# main_sec_mmr_MAIN_SEC_MMR_CFG2_45900000h register map
Vendor: Texas Instruments
Peripheral module from a debugger description file (folder am62D).
Registers are 32-bit, access per field, reset 0xAA unless marked. A register's access mark holds for its fields unless they carry their own. Offsets are as the file gives them; lines under a group give offsets from that group; [hi:lo] are bit positions; {n}, {i} and the like mark numbered series; 'fields as' and 'values as' point back to an identical list; <NAME> marks a mode.

## main_sec_mmr_CFG2
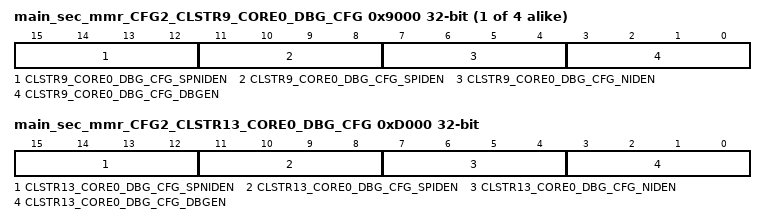
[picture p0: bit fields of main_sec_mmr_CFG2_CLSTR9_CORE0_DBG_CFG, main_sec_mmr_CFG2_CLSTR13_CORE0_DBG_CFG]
{0x9000+0x40*i} main_sec_mmr_CFG2_CLSTR9_CORE{i}_DBG_CFG (i=0..3)
  [15:12] CLSTR9_CORE{i}_DBG_CFG_SPNIDEN ro — Core{i} Secure Non-Invasive debug activate.This is a fault tolerant bitfield that must be set 4'hA to activate4'b1010 - Activatedothers - Deactivated Reset Source: sys_por_rst_n
  [11:8] CLSTR9_CORE{i}_DBG_CFG_SPIDEN ro — Core{i} Secure Invasive debug activate.This is a fault tolerant bitfield that must be set 4'hA to activate4'b1010 - Activatedothers - Deactivated Reset Source: sys_por_rst_n
  [7:4] CLSTR9_CORE{i}_DBG_CFG_NIDEN rw — Core{i} Non-Invasive debug activate.This is a fault tolerant bitfield that must be set 4'hA to activate4'b1010 - Activatedothers - Deactivated Reset Source: sys_por_rst_n
  [3:0] CLSTR9_CORE{i}_DBG_CFG_DBGEN rw — Core{i} Invasive debug activate.This is a fault tolerant bitfield that must be set 4'hA to activate4'b1010 - Activatedothers - Deactivated Reset Source: sys_por_rst_n
0xD000 main_sec_mmr_CFG2_CLSTR13_CORE0_DBG_CFG
  [15:12] CLSTR13_CORE0_DBG_CFG_SPNIDEN ro — Core0 Secure Non-Invasive debug activate.This is a fault tolerant bitfield that must be set 4'hA to activate4'b1010 - Activatedothers - Deactivated Reset Source: sys_por_rst_n
  [11:8] CLSTR13_CORE0_DBG_CFG_SPIDEN ro — Core0 Secure Invasive debug activate.This is a fault tolerant bitfield that must be set 4'hA to activate4'b1010 - Activatedothers - Deactivated Reset Source: sys_por_rst_n
  [7:4] CLSTR13_CORE0_DBG_CFG_NIDEN rw — Core0 Non-Invasive debug activate.This is a fault tolerant bitfield that must be set 4'hA to activate4'b1010 - Activatedothers - Deactivated Reset Source: sys_por_rst_n
  [3:0] CLSTR13_CORE0_DBG_CFG_DBGEN rw — Core0 Invasive debug activate.This is a fault tolerant bitfield that must be set 4'hA to activate4'b1010 - Activatedothers - Deactivated Reset Source: sys_por_rst_n
